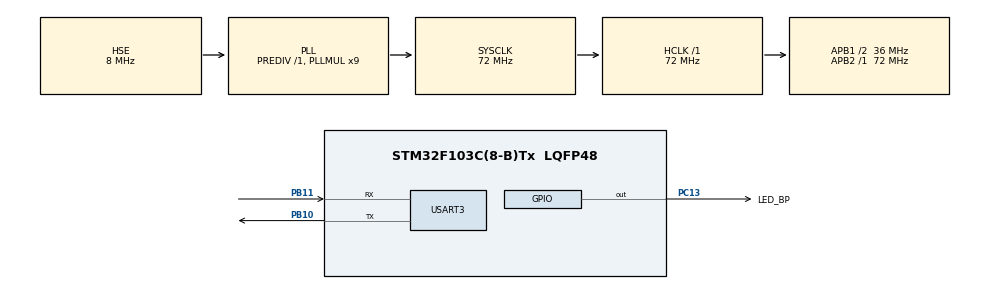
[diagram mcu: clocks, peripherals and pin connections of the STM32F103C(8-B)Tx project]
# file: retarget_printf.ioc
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Mcu.Family=STM32F1
RCC.PLLSourceVirtual=RCC_PLLSOURCE_HSE
PC15-OSC32_OUT.Mode=LSE-External-Oscillator
PD1-OSC_OUT.Mode=HSE-External-Oscillator
PB10.Mode=Asynchronous
PC13-TAMPER-RTC.Signal=GPIO_Output
PD0-OSC_IN.Signal=RCC_OSC_IN
RCC.APB1CLKDivider=RCC_HCLK_DIV2
PC14-OSC32_IN.Signal=RCC_OSC32_IN
PB11.Signal=USART3_RX
RCC.SYSCLKSource=RCC_SYSCLKSOURCE_PLLCLK
ProjectManager.StackSize=0x400
PD1-OSC_OUT.Signal=RCC_OSC_OUT
PA13.Signal=SYS_JTMS-SWDIO
PB11.Mode=Asynchronous
ProjectManager.TargetToolchain=STM32CubeIDE
RCC.HCLKFreq_Value=72000000
RCC.APB2TimFreq_Value=72000000
RCC.USBFreq_Value=72000000
PC15-OSC32_OUT.Signal=RCC_OSC32_OUT
RCC.AHBFreq_Value=72000000
PB10.Signal=USART3_TX
PD0-OSC_IN.Mode=HSE-External-Oscillator
board=custom
RCC.PLLMUL=RCC_PLL_MUL9
PC13-TAMPER-RTC.GPIO_Label=LED_BP
RCC.APB2Freq_Value=72000000
PC13-TAMPER-RTC.PinState=GPIO_PIN_SET
PC14-OSC32_IN.Mode=LSE-External-Oscillator
PA14.Mode=Serial_Wire
PA13.Mode=Serial_Wire
Mcu.Name=STM32F103C(8-B)Tx
RCC.SYSCLKFreq_VALUE=72000000
Mcu.Package=LQFP48
USART3.VirtualMode=VM_ASYNC
PA14.Signal=SYS_JTCK-SWCLK
ProjectManager.HeapSize=0x200
NVIC.PriorityGroup=NVIC_PRIORITYGROUP_4
RCC.APB1TimFreq_Value=72000000
RCC.APB1Freq_Value=36000000

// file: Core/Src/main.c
/* USER CODE BEGIN Header */
/**
 ******************************************************************************
 * @file           : main.c
 * @brief          : Main program body
 ******************************************************************************
 * @attention
 *
 * <h2><center>&copy; Copyright (c) 2021 STMicroelectronics.
 * All rights reserved.</center></h2>
 *
 * This software component is licensed by ST under BSD 3-Clause license,
 * the "License"; You may not use this file except in compliance with the
 * License. You may obtain a copy of the License at:
 *                        opensource.org/licenses/BSD-3-Clause
 *
 ******************************************************************************
 */
/* USER CODE END Header */
#include "main.h"

/* USER CODE BEGIN Includes */
#include <stdio.h>
/* USER CODE END Includes */

UART_HandleTypeDef huart3;

/* USER CODE BEGIN PV */
static uint32_t cont_ms;
/* USER CODE END PV */

void SystemClock_Config(void);
static void MX_GPIO_Init(void);
static void MX_USART3_UART_Init(void);

/* USER CODE BEGIN 0 */

/** @brief Retarget printf() to UART3 */
int __io_putchar(int ch)
{
	HAL_UART_Transmit(&huart3, (uint8_t *)&ch, 1, 10);
	return ch;
}

/** @brief SysTick interrupt callback */
void HAL_IncTick(void)
{
	uwTick += uwTickFreq;
	cont_ms++;
}

/* USER CODE END 0 */

int main(void)
{
	/* USER CODE BEGIN 1 */
	uint32_t i = 0, result;
	/* USER CODE END 1 */

	/* MCU Configuration--------------------------------------------------------*/

	/* Reset of all peripherals, Initializes the Flash interface and the Systick. */
	HAL_Init();

	/* Configure the system clock */
	SystemClock_Config();

	/* Initialize all configured peripherals */
	MX_GPIO_Init();
	MX_USART3_UART_Init();
	/* USER CODE BEGIN 2 */

	/* Enable the DWT cycle counter */
	DWT->CTRL |= DWT_CTRL_CYCCNTENA_Msk;

	/* Print the current system clock frequency over UART3 */
	debug_print("SystemCoreClock: %lu Hz\r\n", HAL_RCC_GetSysClockFreq());

	/* USER CODE END 2 */

	/* Infinite loop */
	/* USER CODE BEGIN WHILE */
	while (1)
	{
		if (cont_ms > 2000) {
			cont_ms = 0;

			DWT->CYCCNT = 0;
			result = i * 5;
			debug_print("Integer arithmetic:        result = %lu, %lu cycles\r\n", result, DWT->CYCCNT);

			DWT->CYCCNT = 0;
			result = i * 5.0;
			debug_print("Floating-point arithmetic: result = %lu, %lu cycles\r\n", result, DWT->CYCCNT);

			i++;
		}

		__WFI();

		/* USER CODE END WHILE */

	}
}

void SystemClock_Config(void)
{
	RCC_OscInitTypeDef RCC_OscInitStruct = {0};
	RCC_ClkInitTypeDef RCC_ClkInitStruct = {0};

	/** Initializes the RCC Oscillators according to the specified parameters
	 * in the RCC_OscInitTypeDef structure.
	 */
	RCC_OscInitStruct.OscillatorType = RCC_OSCILLATORTYPE_HSE;
	RCC_OscInitStruct.HSEState = RCC_HSE_ON;
	RCC_OscInitStruct.HSEPredivValue = RCC_HSE_PREDIV_DIV1;
	RCC_OscInitStruct.HSIState = RCC_HSI_ON;
	RCC_OscInitStruct.PLL.PLLState = RCC_PLL_ON;
	RCC_OscInitStruct.PLL.PLLSource = RCC_PLLSOURCE_HSE;
	RCC_OscInitStruct.PLL.PLLMUL = RCC_PLL_MUL9;
	if (HAL_RCC_OscConfig(&RCC_OscInitStruct) != HAL_OK)
	{
		Error_Handler();
	}
	/** Initializes the CPU, AHB and APB buses clocks
	 */
	RCC_ClkInitStruct.ClockType = RCC_CLOCKTYPE_HCLK|RCC_CLOCKTYPE_SYSCLK
			|RCC_CLOCKTYPE_PCLK1|RCC_CLOCKTYPE_PCLK2;
	RCC_ClkInitStruct.SYSCLKSource = RCC_SYSCLKSOURCE_PLLCLK;
	RCC_ClkInitStruct.AHBCLKDivider = RCC_SYSCLK_DIV1;
	RCC_ClkInitStruct.APB1CLKDivider = RCC_HCLK_DIV2;
	RCC_ClkInitStruct.APB2CLKDivider = RCC_HCLK_DIV1;

	if (HAL_RCC_ClockConfig(&RCC_ClkInitStruct, FLASH_LATENCY_2) != HAL_OK)
	{
		Error_Handler();
	}
}

static void MX_USART3_UART_Init(void)
{

	huart3.Instance = USART3;
	huart3.Init.BaudRate = 115200;
	huart3.Init.WordLength = UART_WORDLENGTH_8B;
	huart3.Init.StopBits = UART_STOPBITS_1;
	huart3.Init.Parity = UART_PARITY_NONE;
	huart3.Init.Mode = UART_MODE_TX_RX;
	huart3.Init.HwFlowCtl = UART_HWCONTROL_NONE;
	huart3.Init.OverSampling = UART_OVERSAMPLING_16;
	if (HAL_UART_Init(&huart3) != HAL_OK)
	{
		Error_Handler();
	}

}

static void MX_GPIO_Init(void)
{
	GPIO_InitTypeDef GPIO_InitStruct = {0};

	/* GPIO Ports Clock Enable */
	__HAL_RCC_GPIOC_CLK_ENABLE();
	__HAL_RCC_GPIOD_CLK_ENABLE();
	__HAL_RCC_GPIOB_CLK_ENABLE();
	__HAL_RCC_GPIOA_CLK_ENABLE();

	/*Configure GPIO pin Output Level */
	HAL_GPIO_WritePin(LED_BP_GPIO_Port, LED_BP_Pin, GPIO_PIN_SET);

	/*Configure GPIO pin : LED_BP_Pin */
	GPIO_InitStruct.Pin = LED_BP_Pin;
	GPIO_InitStruct.Mode = GPIO_MODE_OUTPUT_PP;
	GPIO_InitStruct.Pull = GPIO_NOPULL;
	GPIO_InitStruct.Speed = GPIO_SPEED_FREQ_LOW;
	HAL_GPIO_Init(LED_BP_GPIO_Port, &GPIO_InitStruct);

}

void Error_Handler(void)
{
	__disable_irq();
	while (1)
	{
	}
}

/************************ (C) COPYRIGHT STMicroelectronics *****END OF FILE****/
